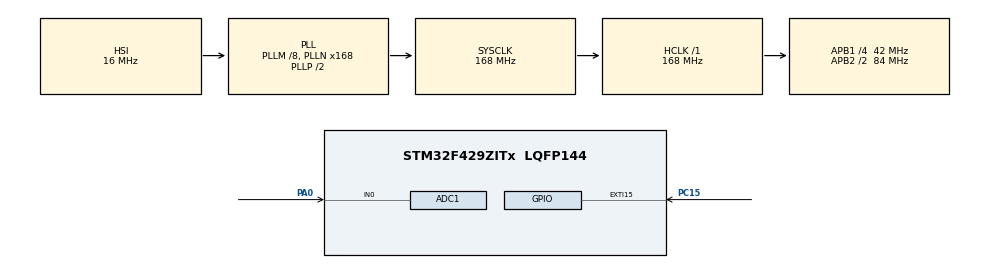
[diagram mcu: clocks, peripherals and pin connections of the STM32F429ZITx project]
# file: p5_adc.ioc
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ADC1.Channel-4\#ChannelRegularConversion=ADC_CHANNEL_0
ADC1.Channel-5\#ChannelRegularConversion=ADC_CHANNEL_TEMPSENSOR
ADC1.ContinuousConvMode=ENABLE
ADC1.NbrOfConversion=3
ADC1.NbrOfConversionFlag=1
ADC1.Rank-4\#ChannelRegularConversion=2
ADC1.Rank-5\#ChannelRegularConversion=3
ADC1.SamplingTime-4\#ChannelRegularConversion=ADC_SAMPLETIME_56CYCLES
ADC1.SamplingTime-5\#ChannelRegularConversion=ADC_SAMPLETIME_56CYCLES
ADC1.ScanConvMode=ENABLE
ADC1.master=1
Mcu.Family=STM32F4
Mcu.Name=STM32F429ZITx
Mcu.Package=LQFP144
NVIC.ADC_IRQn=true\:0\:0\:false\:false\:true\:true\:true\:true
NVIC.PriorityGroup=NVIC_PRIORITYGROUP_4
PA0/WKUP.Signal=ADCx_IN0
PC15/OSC32_OUT.Signal=GPXTI15
PH0/OSC_IN.Mode=HSE-External-Oscillator
PH0/OSC_IN.Signal=RCC_OSC_IN
PH1/OSC_OUT.Mode=HSE-External-Oscillator
PH1/OSC_OUT.Signal=RCC_OSC_OUT
ProjectManager.HeapSize=0x200
ProjectManager.StackSize=0x400
ProjectManager.TargetToolchain=STM32CubeIDE
RCC.48MHZClocksFreq_Value=84000000
RCC.AHBFreq_Value=168000000
RCC.APB1CLKDivider=RCC_HCLK_DIV4
RCC.APB1Freq_Value=42000000
RCC.APB1TimFreq_Value=84000000
RCC.APB2CLKDivider=RCC_HCLK_DIV2
RCC.APB2Freq_Value=84000000
RCC.APB2TimFreq_Value=168000000
RCC.CortexFreq_Value=168000000
RCC.HCLKFreq_Value=168000000
RCC.HSE_VALUE=8000000
RCC.HSI_VALUE=16000000
RCC.LSE_VALUE=32768
RCC.PLLM=8
RCC.PLLN=168
RCC.SYSCLKFreq_VALUE=168000000
RCC.SYSCLKSource=RCC_SYSCLKSOURCE_PLLCLK
RCC.VCOOutputFreq_Value=336000000
SH.ADCx_IN0.0=ADC1_IN0,IN0
TIM1.Period=1000
TIM1.Prescaler=15
VP_ADC1_TempSens_Input.Mode=IN-TempSens
VP_ADC1_Vref_Input.Mode=IN-Vrefint
VP_TIM1_VS_ClockSourceINT.Mode=Internal
board=custom

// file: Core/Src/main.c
/* USER CODE BEGIN Header */
/**
  ******************************************************************************
  * @file           : main.c
  * @brief          : Main program body
  ******************************************************************************
  * @attention
  *
  * Copyright (c) 2025 STMicroelectronics.
  * All rights reserved.
  *
  * This software is licensed under terms that can be found in the LICENSE file
  * in the root directory of this software component.
  * If no LICENSE file comes with this software, it is provided AS-IS.
  *
  ******************************************************************************
  */
/* USER CODE END Header */
#include "main.h"

/* USER CODE BEGIN Includes */

#define VREFIN_CAL ((uint16_t*)((uint32_t)0x1FFF7A2A))
#define V25 (float) 0.76
#define Avg_slope (float) 0.0025

volatile uint16_t adc1_value[3];
volatile float Vadc1= 0, Vsense= 0, Vdda= 0, temp=0;
volatile int count =0;

/* USER CODE END Includes */

ADC_HandleTypeDef hadc1;

TIM_HandleTypeDef htim1;

void SystemClock_Config(void);
static void MX_GPIO_Init(void);
static void MX_ADC1_Init(void);
static void MX_TIM1_Init(void);

/* USER CODE BEGIN 0 */
void HAL_ADC_ConvCpltCallback(ADC_HandleTypeDef *hadc)
{
	if(__HAL_ADC_GET_FLAG(&hadc1, ADC_FLAG_EOC) != RESET)
	{
		adc1_value[count] = HAL_ADC_GetValue(&hadc1);
		count++;
		if(count == 3)count=0;

		Vdda = (float) 3.3 * (*VREFIN_CAL) / adc1_value[1];
		Vadc1 = Vdda * adc1_value[0] / 4095;
		Vsense = Vdda * adc1_value[2] / 4095;

		temp = ((Vsense - V25) / Avg_slope ) + 25;

	}

}
/* USER CODE END 0 */

int main(void)
{

  /* MCU Configuration--------------------------------------------------------*/

  /* Reset of all peripherals, Initializes the Flash interface and the Systick. */
  HAL_Init();

  /* Configure the system clock */
  SystemClock_Config();

  /* Initialize all configured peripherals */
  MX_GPIO_Init();
  MX_ADC1_Init();
  MX_TIM1_Init();
  /* USER CODE BEGIN 2 */
  HAL_ADC_Start_IT(&hadc1);
  /* USER CODE END 2 */

  /* Infinite loop */
  while (1)
  {

  }
}

void SystemClock_Config(void)
{
  RCC_OscInitTypeDef RCC_OscInitStruct = {0};
  RCC_ClkInitTypeDef RCC_ClkInitStruct = {0};

  /** Configure the main internal regulator output voltage
  */
  __HAL_RCC_PWR_CLK_ENABLE();
  __HAL_PWR_VOLTAGESCALING_CONFIG(PWR_REGULATOR_VOLTAGE_SCALE1);

  /** Initializes the RCC Oscillators according to the specified parameters
  * in the RCC_OscInitTypeDef structure.
  */
  RCC_OscInitStruct.OscillatorType = RCC_OSCILLATORTYPE_HSI;
  RCC_OscInitStruct.HSIState = RCC_HSI_ON;
  RCC_OscInitStruct.HSICalibrationValue = RCC_HSICALIBRATION_DEFAULT;
  RCC_OscInitStruct.PLL.PLLState = RCC_PLL_ON;
  RCC_OscInitStruct.PLL.PLLSource = RCC_PLLSOURCE_HSI;
  RCC_OscInitStruct.PLL.PLLM = 8;
  RCC_OscInitStruct.PLL.PLLN = 168;
  RCC_OscInitStruct.PLL.PLLP = RCC_PLLP_DIV2;
  RCC_OscInitStruct.PLL.PLLQ = 4;
  if (HAL_RCC_OscConfig(&RCC_OscInitStruct) != HAL_OK)
  {
    Error_Handler();
  }

  /** Initializes the CPU, AHB and APB buses clocks
  */
  RCC_ClkInitStruct.ClockType = RCC_CLOCKTYPE_HCLK|RCC_CLOCKTYPE_SYSCLK
                              |RCC_CLOCKTYPE_PCLK1|RCC_CLOCKTYPE_PCLK2;
  RCC_ClkInitStruct.SYSCLKSource = RCC_SYSCLKSOURCE_PLLCLK;
  RCC_ClkInitStruct.AHBCLKDivider = RCC_SYSCLK_DIV1;
  RCC_ClkInitStruct.APB1CLKDivider = RCC_HCLK_DIV4;
  RCC_ClkInitStruct.APB2CLKDivider = RCC_HCLK_DIV2;

  if (HAL_RCC_ClockConfig(&RCC_ClkInitStruct, FLASH_LATENCY_5) != HAL_OK)
  {
    Error_Handler();
  }
}

static void MX_ADC1_Init(void)
{

  ADC_ChannelConfTypeDef sConfig = {0};

  /** Configure the global features of the ADC (Clock, Resolution, Data Alignment and number of conversion)
  */
  hadc1.Instance = ADC1;
  hadc1.Init.ClockPrescaler = ADC_CLOCK_SYNC_PCLK_DIV4;
  hadc1.Init.Resolution = ADC_RESOLUTION_12B;
  hadc1.Init.ScanConvMode = ENABLE;
  hadc1.Init.ContinuousConvMode = ENABLE;
  hadc1.Init.DiscontinuousConvMode = DISABLE;
  hadc1.Init.ExternalTrigConvEdge = ADC_EXTERNALTRIGCONVEDGE_NONE;
  hadc1.Init.ExternalTrigConv = ADC_SOFTWARE_START;
  hadc1.Init.DataAlign = ADC_DATAALIGN_RIGHT;
  hadc1.Init.NbrOfConversion = 3;
  hadc1.Init.DMAContinuousRequests = DISABLE;
  hadc1.Init.EOCSelection = ADC_EOC_SINGLE_CONV;
  if (HAL_ADC_Init(&hadc1) != HAL_OK)
  {
    Error_Handler();
  }

  /** Configure for the selected ADC regular channel its corresponding rank in the sequencer and its sample time.
  */
  sConfig.Channel = ADC_CHANNEL_0;
  sConfig.Rank = 2;
  sConfig.SamplingTime = ADC_SAMPLETIME_56CYCLES;
  if (HAL_ADC_ConfigChannel(&hadc1, &sConfig) != HAL_OK)
  {
    Error_Handler();
  }

  /** Configure for the selected ADC regular channel its corresponding rank in the sequencer and its sample time.
  */
  sConfig.Channel = ADC_CHANNEL_TEMPSENSOR;
  sConfig.Rank = 3;
  if (HAL_ADC_ConfigChannel(&hadc1, &sConfig) != HAL_OK)
  {
    Error_Handler();
  }

}

static void MX_TIM1_Init(void)
{

  TIM_ClockConfigTypeDef sClockSourceConfig = {0};
  TIM_MasterConfigTypeDef sMasterConfig = {0};

  htim1.Instance = TIM1;
  htim1.Init.Prescaler = 15;
  htim1.Init.CounterMode = TIM_COUNTERMODE_UP;
  htim1.Init.Period = 1000;
  htim1.Init.ClockDivision = TIM_CLOCKDIVISION_DIV1;
  htim1.Init.RepetitionCounter = 0;
  htim1.Init.AutoReloadPreload = TIM_AUTORELOAD_PRELOAD_DISABLE;
  if (HAL_TIM_Base_Init(&htim1) != HAL_OK)
  {
    Error_Handler();
  }
  sClockSourceConfig.ClockSource = TIM_CLOCKSOURCE_INTERNAL;
  if (HAL_TIM_ConfigClockSource(&htim1, &sClockSourceConfig) != HAL_OK)
  {
    Error_Handler();
  }
  sMasterConfig.MasterOutputTrigger = TIM_TRGO_RESET;
  sMasterConfig.MasterSlaveMode = TIM_MASTERSLAVEMODE_DISABLE;
  if (HAL_TIMEx_MasterConfigSynchronization(&htim1, &sMasterConfig) != HAL_OK)
  {
    Error_Handler();
  }

}

static void MX_GPIO_Init(void)
{
  GPIO_InitTypeDef GPIO_InitStruct = {0};

  /* GPIO Ports Clock Enable */
  __HAL_RCC_GPIOC_CLK_ENABLE();
  __HAL_RCC_GPIOH_CLK_ENABLE();
  __HAL_RCC_GPIOA_CLK_ENABLE();

  /*Configure GPIO pin : PC15 */
  GPIO_InitStruct.Pin = GPIO_PIN_15;
  GPIO_InitStruct.Mode = GPIO_MODE_IT_RISING;
  GPIO_InitStruct.Pull = GPIO_NOPULL;
  HAL_GPIO_Init(GPIOC, &GPIO_InitStruct);

}

void Error_Handler(void)
{
  __disable_irq();
  while (1)
  {
  }
}
